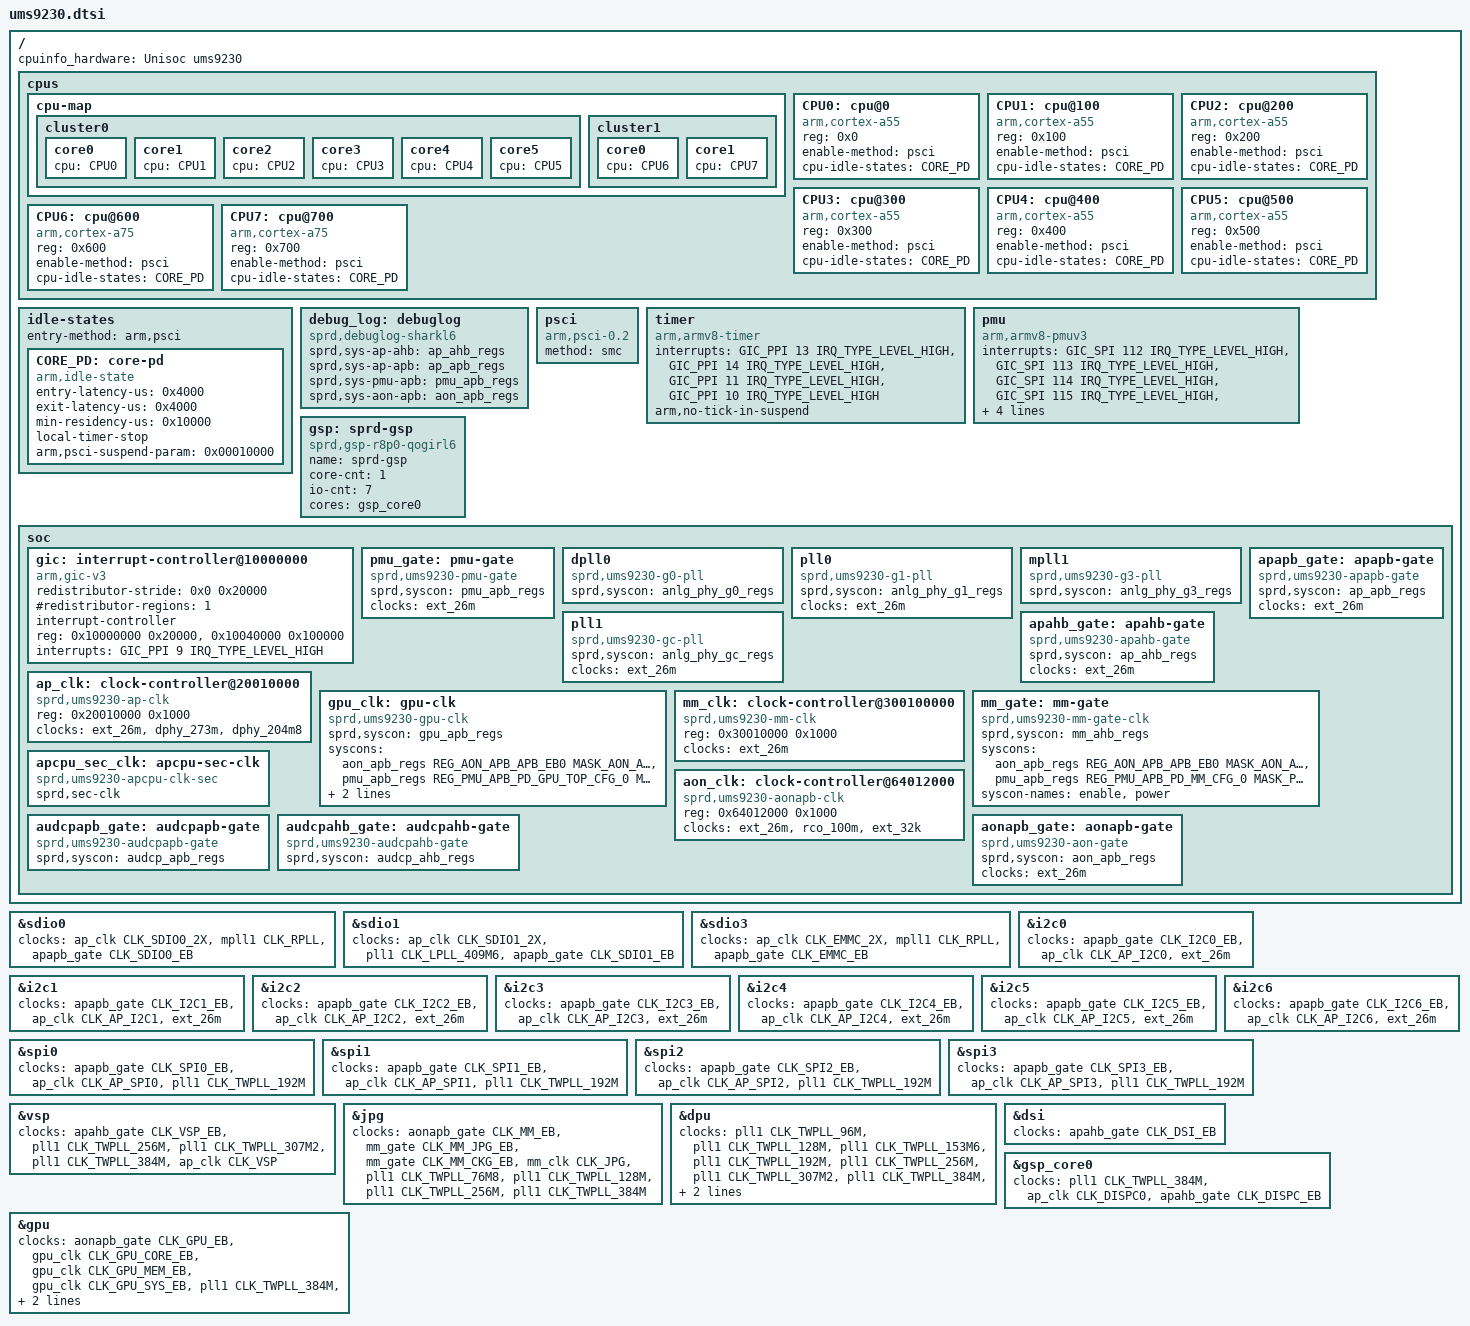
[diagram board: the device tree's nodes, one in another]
// SPDX-License-Identifier: GPL-2.0-only
/*
 * Unisoc Qogirl6 platform DTS file
 *
 * Copyright (C) 2020, Unisoc Inc.
 */

#include <dt-bindings/interrupt-controller/arm-gic.h>
#include <dt-bindings/clock/sprd,ums9230-clk.h>
#include "qogirl6.dtsi"
#include "ums9230-qos.dtsi"

/ {
	cpuinfo_hardware = "Unisoc ums9230";

	cpus {
		#address-cells = <1>;
		#size-cells = <0>;

		cpu-map {
			cluster0 {
				core0 {
					cpu = <&CPU0>;
				};
				core1 {
					cpu = <&CPU1>;
				};
				core2 {
					cpu = <&CPU2>;
				};
				core3 {
					cpu = <&CPU3>;
				};
				core4 {
					cpu = <&CPU4>;
				};
				core5 {
					cpu = <&CPU5>;
				};
			};
			cluster1 {
				core0 {
					cpu = <&CPU6>;
				};
				core1 {
					cpu = <&CPU7>;
				};
			};
		};

		CPU0: cpu@0 {
			device_type = "cpu";
			compatible = "arm,cortex-a55";
			reg = <0x0>;
			enable-method = "psci";
			cpu-idle-states = <&CORE_PD>;
		};
		CPU1: cpu@100 {
			device_type = "cpu";
			compatible = "arm,cortex-a55";
			reg = <0x100>;
			enable-method = "psci";
			cpu-idle-states = <&CORE_PD>;
		};
		CPU2: cpu@200 {
			device_type = "cpu";
			compatible = "arm,cortex-a55";
			reg = <0x200>;
			enable-method = "psci";
			cpu-idle-states = <&CORE_PD>;
		};
		CPU3: cpu@300 {
			device_type = "cpu";
			compatible = "arm,cortex-a55";
			reg = <0x300>;
			enable-method = "psci";
			cpu-idle-states = <&CORE_PD>;
		};
		CPU4: cpu@400 {
			device_type = "cpu";
			compatible = "arm,cortex-a55";
			reg = <0x400>;
			enable-method = "psci";
			cpu-idle-states = <&CORE_PD>;
		};
		CPU5: cpu@500 {
			device_type = "cpu";
			compatible = "arm,cortex-a55";
			reg = <0x500>;
			enable-method = "psci";
			cpu-idle-states = <&CORE_PD>;
		};
		CPU6: cpu@600 {
			device_type = "cpu";
			compatible = "arm,cortex-a75";
			reg = <0x600>;
			enable-method = "psci";
			cpu-idle-states = <&CORE_PD>;
		};
		CPU7: cpu@700 {
			device_type = "cpu";
			compatible = "arm,cortex-a75";
			reg = <0x700>;
			enable-method = "psci";
			cpu-idle-states = <&CORE_PD>;
		};
	};

	idle-states {
		entry-method = "arm,psci";
		CORE_PD: core-pd {
			compatible = "arm,idle-state";
			entry-latency-us = <0x4000>;
			exit-latency-us = <0x4000>;
			min-residency-us = <0x10000>;
			local-timer-stop;
			arm,psci-suspend-param = <0x00010000>;
		};
	};

	debug_log: debuglog {
		compatible = "sprd,debuglog-sharkl6";

		sprd,sys-ap-ahb = <&ap_ahb_regs>;
		sprd,sys-ap-apb = <&ap_apb_regs>;
		sprd,sys-pmu-apb = <&pmu_apb_regs>;
		sprd,sys-aon-apb = <&aon_apb_regs>;
	};

	psci {
		compatible = "arm,psci-0.2";
		method = "smc";
	};

	timer {
		compatible = "arm,armv8-timer";
		interrupts = <GIC_PPI 13 IRQ_TYPE_LEVEL_HIGH>, /* Physical Secure PPI */
			     <GIC_PPI 14 IRQ_TYPE_LEVEL_HIGH>, /* Physical Non-Secure PPI */
			     <GIC_PPI 11 IRQ_TYPE_LEVEL_HIGH>, /* Virtual PPI */
			     <GIC_PPI 10 IRQ_TYPE_LEVEL_HIGH>; /* Hipervisor PPI */
		arm,no-tick-in-suspend;
	};

	pmu {
		compatible = "arm,armv8-pmuv3";
		interrupts = <GIC_SPI 112 IRQ_TYPE_LEVEL_HIGH>,
				<GIC_SPI 113 IRQ_TYPE_LEVEL_HIGH>,
				<GIC_SPI 114 IRQ_TYPE_LEVEL_HIGH>,
				<GIC_SPI 115 IRQ_TYPE_LEVEL_HIGH>,
				<GIC_SPI 116 IRQ_TYPE_LEVEL_HIGH>,
				<GIC_SPI 117 IRQ_TYPE_LEVEL_HIGH>,
				<GIC_SPI 118 IRQ_TYPE_LEVEL_HIGH>,
				<GIC_SPI 119 IRQ_TYPE_LEVEL_HIGH>;
	};

	gsp: sprd-gsp {
		compatible = "sprd,gsp-r8p0-qogirl6";
		name = "sprd-gsp";
		core-cnt = <1>;
		io-cnt = <7>;
		cores = <&gsp_core0>;
	};

	soc {
		gic: interrupt-controller@10000000 {
			compatible = "arm,gic-v3";
			#interrupt-cells = <3>;
			#address-cells = <1>;
			#size-cells = <1>;
			ranges;
			redistributor-stride = <0x0 0x20000>;	/* 128KB stride */
			#redistributor-regions = <1>;
			interrupt-controller;
			reg = <0x10000000 0x20000>,	/* GICD */
				  <0x10040000 0x100000>;	/* GICR */
			interrupts = <GIC_PPI 9 IRQ_TYPE_LEVEL_HIGH>;
		};

		pmu_gate: pmu-gate {
			compatible = "sprd,ums9230-pmu-gate";
			sprd,syscon = <&pmu_apb_regs>; /* 0x64020000 */
			clocks = <&ext_26m>;
			clock-names = "ext-26m";
			#clock-cells = <1>;
		};

		dpll0: dpll0 {
			compatible = "sprd,ums9230-g0-pll";
			sprd,syscon = <&anlg_phy_g0_regs>; /* 0x64550000 */
			#clock-cells = <1>;
		};

		pll0: pll0 {
			compatible = "sprd,ums9230-g1-pll";
			sprd,syscon = <&anlg_phy_g1_regs>; /* 0x64560000 */
			clocks = <&ext_26m>;
			#clock-cells = <1>;
		};

		mpll1: mpll1 {
			compatible = "sprd,ums9230-g3-pll";
			sprd,syscon = <&anlg_phy_g3_regs>; /* 0x64580000 */
			#clock-cells = <1>;
		};

		pll1: pll1 {
			compatible = "sprd,ums9230-gc-pll";
			sprd,syscon = <&anlg_phy_gc_regs>; /* 0x645a0000 */
			clocks = <&ext_26m>;
			clock-names = "ext-26m";
			#clock-cells = <1>;
		};

		apapb_gate: apapb-gate {
			compatible = "sprd,ums9230-apapb-gate";
			sprd,syscon = <&ap_apb_regs>; /* 0x20000000 */
			clocks = <&ext_26m>;
			clock-names = "ext-26m";
			#clock-cells = <1>;
		};

		apahb_gate: apahb-gate {
			compatible = "sprd,ums9230-apahb-gate";
			sprd,syscon = <&ap_ahb_regs>; /* 0x20400000 */
			clocks = <&ext_26m>;
			clock-names = "ext-26m";
			#clock-cells = <1>;
		};

		ap_clk: clock-controller@20010000 {
			compatible = "sprd,ums9230-ap-clk";
			reg = <0x20010000 0x1000>;
			clocks = <&ext_26m>, <&dphy_273m>, <&dphy_204m8>;
			clock-names = "ext-26m", "dphy-273m", "dphy-204m8";
			#clock-cells = <1>;
		};

		gpu_clk: gpu-clk {
			compatible = "sprd,ums9230-gpu-clk";
			sprd,syscon = <&gpu_apb_regs>; /* 0x23000000 */
			syscons = <&aon_apb_regs REG_AON_APB_APB_EB0 MASK_AON_APB_GPU_EB>,
				<&pmu_apb_regs REG_PMU_APB_PD_GPU_TOP_CFG_0 MASK_PMU_APB_PD_GPU_TOP_FORCE_SHUTDOWN>;
			syscon-names = "enable", "power";
			clocks = <&ext_26m>;
			clock-names = "ext-26m";
			#clock-cells = <1>;
		};

		mm_clk: clock-controller@300100000 {
			compatible = "sprd,ums9230-mm-clk";
			reg = <0x30010000 0x1000>;
			clocks = <&ext_26m>;
			clock-names = "ext-26m";
			#clock-cells = <1>;
		};

		mm_gate: mm-gate {
			compatible = "sprd,ums9230-mm-gate-clk";
			sprd,syscon = <&mm_ahb_regs>; /* 0x30000000 */
			syscons = <&aon_apb_regs REG_AON_APB_APB_EB0 MASK_AON_APB_MM_EB>,
				<&pmu_apb_regs  REG_PMU_APB_PD_MM_CFG_0 MASK_PMU_APB_PD_MM_FORCE_SHUTDOWN>;
			syscon-names = "enable", "power";
			#clock-cells = <1>;
		};

		aon_clk: clock-controller@64012000 {
			compatible = "sprd,ums9230-aonapb-clk";
			reg = <0x64012000 0x1000>;
			clocks = <&ext_26m>, <&rco_100m>, <&ext_32k>;
			clock-names = "ext-26m", "rco-100m", "ext-32k";
			#clock-cells = <1>;
		};

		apcpu_sec_clk: apcpu-sec-clk {
			compatible = "sprd,ums9230-apcpu-clk-sec";
			sprd,sec-clk;
			#clock-cells = <1>;
	       };

		audcpapb_gate: audcpapb-gate {
			compatible = "sprd,ums9230-audcpapb-gate";
			sprd,syscon = <&audcp_apb_regs>; /* 0x5600d000 */
			#clock-cells = <1>;
		};

		audcpahb_gate: audcpahb-gate {
			compatible = "sprd,ums9230-audcpahb-gate";
			sprd,syscon = <&audcp_ahb_regs>; /* 0x56000000 */
			#clock-cells = <1>;
		};

		aonapb_gate: aonapb-gate {
			compatible = "sprd,ums9230-aon-gate";
			sprd,syscon = <&aon_apb_regs>; /* 0x64000000 */
			clocks = <&ext_26m>;
			clock-names = "ext-26m";
			#clock-cells = <1>;
		};
	};
};

&sdio0 {
	clock-names = "sdio_clk", "sdio_clk_source",
		      "sdio_ahb_enable";
	clocks = <&ap_clk CLK_SDIO0_2X>,
		 <&mpll1 CLK_RPLL>,
		 <&apapb_gate CLK_SDIO0_EB>;
};

&sdio1 {
	clock-names = "sdio_clk","sdio_clk_source","sdio_ahb_enable";
	clocks = <&ap_clk CLK_SDIO1_2X>,
		 <&pll1 CLK_LPLL_409M6>,
		 <&apapb_gate CLK_SDIO1_EB>;
};

&sdio3 {
	clock-names = "sdio_clk","sdio_clk_source","sdio_ahb_enable";
	clocks = <&ap_clk CLK_EMMC_2X>,
		 <&mpll1 CLK_RPLL>,
		 <&apapb_gate CLK_EMMC_EB>;
};

&i2c0 {
	clock-names ="enable", "i2c", "source";
	clocks = <&apapb_gate CLK_I2C0_EB>,
		 <&ap_clk CLK_AP_I2C0>, <&ext_26m>;
};

&i2c1 {
	clock-names ="enable", "i2c", "source";
	clocks = <&apapb_gate CLK_I2C1_EB>,
		 <&ap_clk CLK_AP_I2C1>, <&ext_26m>;
};

&i2c2 {
	clock-names ="enable", "i2c", "source";
	clocks = <&apapb_gate CLK_I2C2_EB>,
		 <&ap_clk CLK_AP_I2C2>, <&ext_26m>;
};

&i2c3 {
	clock-names ="enable", "i2c", "source";
	clocks = <&apapb_gate CLK_I2C3_EB>,
		 <&ap_clk CLK_AP_I2C3>, <&ext_26m>;
};

&i2c4 {
	clock-names ="enable", "i2c", "source";
	clocks = <&apapb_gate CLK_I2C4_EB>,
		 <&ap_clk CLK_AP_I2C4>, <&ext_26m>;
};

&i2c5 {
	clock-names ="enable", "i2c", "source";
	clocks = <&apapb_gate CLK_I2C5_EB>,
		 <&ap_clk CLK_AP_I2C5>, <&ext_26m>;
};

&i2c6 {
	clock-names ="enable", "i2c", "source";
	clocks = <&apapb_gate CLK_I2C6_EB>,
		 <&ap_clk CLK_AP_I2C6>, <&ext_26m>;
};

&spi0 {
	clock-names = "enable", "spi", "source";
	clocks = <&apapb_gate CLK_SPI0_EB>,
		<&ap_clk CLK_AP_SPI0>, <&pll1 CLK_TWPLL_192M>;
};

&spi1 {
	clock-names = "enable", "spi", "source";
	clocks = <&apapb_gate CLK_SPI1_EB>,
		<&ap_clk CLK_AP_SPI1>, <&pll1 CLK_TWPLL_192M>;
};

&spi2 {
	clock-names = "enable", "spi", "source";
	clocks = <&apapb_gate CLK_SPI2_EB>,
		<&ap_clk CLK_AP_SPI2>, <&pll1 CLK_TWPLL_192M>;
};

&spi3 {
	clock-names = "enable", "spi", "source";
	clocks = <&apapb_gate CLK_SPI3_EB>,
		<&ap_clk CLK_AP_SPI3>, <&pll1 CLK_TWPLL_192M>;
};

&vsp {
	clock-names = "clk_ahb_gate_vsp_eb",
			"clk_src_256m",
			"clk_src_307m2",
			"clk_src_384m",
			"clk_vsp";
	clocks = <&apahb_gate CLK_VSP_EB>,
			<&pll1 CLK_TWPLL_256M>,
			<&pll1 CLK_TWPLL_307M2>,
			<&pll1 CLK_TWPLL_384M>,
			<&ap_clk CLK_VSP>;
};

&jpg {
	clock-names = "jpg_domain_eb",
			"jpg_dev_eb",
			"jpg_ckg_eb",
			"jpg_clk",
			"clk_src_76m8",
			"clk_src_128m",
			"clk_src_256m",
			"clk_src_384m";

	clocks = <&aonapb_gate CLK_MM_EB>,
			<&mm_gate CLK_MM_JPG_EB>,
			<&mm_gate CLK_MM_CKG_EB>,
			<&mm_clk CLK_JPG>,
			<&pll1 CLK_TWPLL_76M8>,
			<&pll1 CLK_TWPLL_128M>,
			<&pll1 CLK_TWPLL_256M>,
			<&pll1 CLK_TWPLL_384M>;
};

&dpu {
	clock-names = "clk_src_96m",
			"clk_src_128m",
			"clk_src_153m6",
			"clk_src_192m",
			"clk_src_256m",
			"clk_src_307m2",
			"clk_src_384m",
			"clk_dpu_core",
			"clk_dpu_dpi",
			"clk_ap_ahb_disp_eb";

	clocks = <&pll1 CLK_TWPLL_96M>,
		<&pll1 CLK_TWPLL_128M>,
		<&pll1 CLK_TWPLL_153M6>,
		<&pll1 CLK_TWPLL_192M>,
		<&pll1 CLK_TWPLL_256M>,
		<&pll1 CLK_TWPLL_307M2>,
		<&pll1 CLK_TWPLL_384M>,
		<&ap_clk CLK_DISPC0>,
		<&ap_clk CLK_DISPC0_DPI>,
		<&apahb_gate CLK_DISPC_EB>;
};

&dsi {
	clock-names = "clk_ap_ahb_dsi_eb";
	clocks = <&apahb_gate CLK_DSI_EB>;
};

&gsp_core0 {
	clock-names =	"clk_dpu_core_src",
			"clk_dpu_core",
			"clk_ap_ahb_disp_eb";

	clocks =	<&pll1 CLK_TWPLL_384M>,
			<&ap_clk CLK_DISPC0>,
			<&apahb_gate CLK_DISPC_EB>;
};

&gpu {
	clocks = <&aonapb_gate CLK_GPU_EB>,
	<&gpu_clk CLK_GPU_CORE_EB>,
	<&gpu_clk CLK_GPU_MEM_EB>,
	<&gpu_clk CLK_GPU_SYS_EB>,
	<&pll1 CLK_TWPLL_384M>,
	<&pll1 CLK_TWPLL_512M>,
	<&pll1 CLK_LPLL_614M4>,
	<&pll1 CLK_TWPLL_768M>,
	<&pll1 CLK_GPLL>;
};
